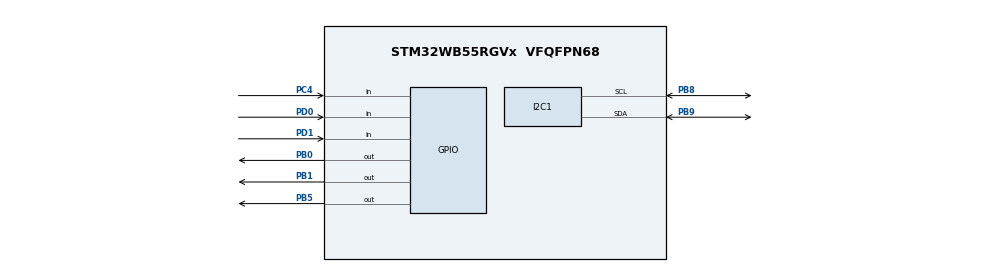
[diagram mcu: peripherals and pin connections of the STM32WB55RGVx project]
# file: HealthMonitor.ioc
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I2C1.Timing=0x00B07CB4
Mcu.Family=STM32WB
Mcu.Name=STM32WB55RGVx
Mcu.Package=VFQFPN68
NUCLEO-WB55RG.BUTTON=1
NUCLEO-WB55RG.BUTTON2=1
NUCLEO-WB55RG.BUTTON3=1
NUCLEO-WB55RG.LD1=true
NUCLEO-WB55RG.LD2=true
NUCLEO-WB55RG.LD3=true
NUCLEO-WB55RG.VCP=true
NVIC.PriorityGroup=NVIC_PRIORITYGROUP_4
OSC_IN.GPIO_Label=RCC_OSC_IN
OSC_IN.Signal=RCC_OSC_IN
OSC_OUT.GPIO_Label=RCC_OSC_OUT
OSC_OUT.Signal=RCC_OSC_OUT
PA11.GPIO_Label=USB_DM
PA11.Signal=USB_DM
PA12.GPIO_Label=USB_DP
PA12.Signal=USB_DP
PA13.GPIO_Label=JTMS
PA13.Signal=SYS_JTMS-SWDIO
PA14.GPIO_Label=JTCK
PA14.Signal=SYS_JTCK-SWCLK
PB0.Signal=GPIO_Output
PB1.Signal=GPIO_Output
PB3.GPIO_Label=JTDO
PB3.Signal=SYS_JTDO-SWO
PB5.Signal=GPIO_Output
PB6.Signal=USART1_TX
PB7.Signal=USART1_RX
PB8.Mode=I2C
PB8.Signal=I2C1_SCL
PB9.Mode=I2C
PB9.Signal=I2C1_SDA
PC13.GPIO_Label=SYS_WKUP2
PC13.Signal=SYS_WKUP2
PC14-OSC32_IN.GPIO_Label=RCC_OSC32_IN
PC14-OSC32_IN.Signal=RCC_OSC32_IN
PC15-OSC32_OUT.GPIO_Label=RCC_OSC32_OUT
PC15-OSC32_OUT.Signal=RCC_OSC32_OUT
PC4.Signal=GPIO_Input
PD0.Signal=GPIO_Input
PD1.Signal=GPIO_Input
ProjectManager.HeapSize=0x200
ProjectManager.StackSize=0x400
ProjectManager.TargetToolchain=STM32CubeIDE
RCC.ADCFreq_Value=128000000
RCC.AHBFreq_Value=32000000
RCC.APB1Freq_Value=32000000
RCC.APB1TimFreq_Value=32000000
RCC.APB2Freq_Value=32000000
RCC.APB2TimFreq_Value=32000000
RCC.APB3Freq_Value=16000000
RCC.CortexFreq_Value=32000000
RCC.HCLKFreq_Value=32000000
RCC.HSE_VALUE=32000000
RCC.HSI48_VALUE=48000000
RCC.HSI_VALUE=16000000
RCC.LSE_VALUE=32768
RCC.MSIClockRange=RCC_MSIRANGE_10
RCC.SMPSCLockSelection=RCC_SMPSCLKSOURCE_HSI
RCC.SMPSCLockSelectionVirtual=RCC_SMPSCLKSOURCE_HSI
RCC.SMPSCLockSelectionVirtualVirtual=RCC_SMPSCLKSOURCE_HSI
RCC.SMPSDivider=1
RCC.SYSCLKFreq_VALUE=32000000
RCC.USBFreq_Value=128000000
RCC.VCOOutputFreq_Value=256000000
VP_MEMORYMAP_VS_MEMORYMAP.Mode=CurAppReg
VP_NUCLEO-WB55RG_VS_BSP_COMMON.Mode=COMMON
board=NUCLEO-WB55RG

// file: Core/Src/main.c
/* USER CODE BEGIN Header */
/**
  ******************************************************************************
  * @file           : main.c
  * @brief          : Main program body
  ******************************************************************************
  * @attention
  *
  * Copyright (c) 2025 STMicroelectronics.
  * All rights reserved.
  *
  * This software is licensed under terms that can be found in the LICENSE file
  * in the root directory of this software component.
  * If no LICENSE file comes with this software, it is provided AS-IS.
  *
  ******************************************************************************
  */
/* USER CODE END Header */
#include "main.h"
#include "max30102.h"

COM_InitTypeDef BspCOMInit;
I2C_HandleTypeDef hi2c1;

void SystemClock_Config(void);
void PeriphCommonClock_Config(void);
static void MX_GPIO_Init(void);
static void MX_I2C1_Init(void);

int main(void)
{

  /* MCU Configuration--------------------------------------------------------*/

  /* Reset of all peripherals, Initializes the Flash interface and the Systick. */
  HAL_Init();

  /* Configure the system clock */
  SystemClock_Config();

  /* Configure the peripherals common clocks */
  PeriphCommonClock_Config();

  /* USER CODE BEGIN SysInit */
//  hi2c1.Instance = I2C1;
//	hi2c1.Init.Timing = 0x00B07CB4;
//	hi2c1.Init.OwnAddress1 = 0;
//	hi2c1.Init.AddressingMode = I2C_ADDRESSINGMODE_7BIT;
//	hi2c1.Init.DualAddressMode = I2C_DUALADDRESS_DISABLE;
//	hi2c1.Init.OwnAddress2 = 0;
//	hi2c1.Init.OwnAddress2Masks = I2C_OA2_NOMASK;
//	hi2c1.Init.GeneralCallMode = I2C_GENERALCALL_DISABLE;
//	hi2c1.Init.NoStretchMode = I2C_NOSTRETCH_DISABLE;
//	if (HAL_I2C_Init(&hi2c1) != HAL_OK)
//	{
//	  Error_Handler();
//	}

  /* USER CODE END SysInit */

  /* Initialize all configured peripherals */
  MX_GPIO_Init();
  MX_I2C1_Init();

  /* Initialize leds */
  BSP_LED_Init(LED_BLUE);
  BSP_LED_Init(LED_GREEN);
  BSP_LED_Init(LED_RED);

  /* Initialize USER push-button, will be used to trigger an interrupt each time it's pressed.*/
  BSP_PB_Init(BUTTON_SW1, BUTTON_MODE_EXTI);
  BSP_PB_Init(BUTTON_SW2, BUTTON_MODE_EXTI);
  BSP_PB_Init(BUTTON_SW3, BUTTON_MODE_EXTI);

  /* Initialize COM1 port (115200, 8 bits (7-bit data + 1 stop bit), no parity */
  BspCOMInit.BaudRate   = 115200;
  BspCOMInit.WordLength = COM_WORDLENGTH_8B;
  BspCOMInit.StopBits   = COM_STOPBITS_1;
  BspCOMInit.Parity     = COM_PARITY_NONE;
  BspCOMInit.HwFlowCtl  = COM_HWCONTROL_NONE;
  if (BSP_COM_Init(COM1, &BspCOMInit) != BSP_ERROR_NONE)
  {
    Error_Handler();
  }

  /* Infinite loop */
  while (1)
  {

  }
}

void SystemClock_Config(void)
{
  RCC_OscInitTypeDef RCC_OscInitStruct = {0};
  RCC_ClkInitTypeDef RCC_ClkInitStruct = {0};

  /** Configure the main internal regulator output voltage
  */
  __HAL_PWR_VOLTAGESCALING_CONFIG(PWR_REGULATOR_VOLTAGE_SCALE1);

  /** Initializes the RCC Oscillators according to the specified parameters
  * in the RCC_OscInitTypeDef structure.
  */
  RCC_OscInitStruct.OscillatorType = RCC_OSCILLATORTYPE_HSI|RCC_OSCILLATORTYPE_MSI;
  RCC_OscInitStruct.HSIState = RCC_HSI_ON;
  RCC_OscInitStruct.MSIState = RCC_MSI_ON;
  RCC_OscInitStruct.HSICalibrationValue = RCC_HSICALIBRATION_DEFAULT;
  RCC_OscInitStruct.MSICalibrationValue = RCC_MSICALIBRATION_DEFAULT;
  RCC_OscInitStruct.MSIClockRange = RCC_MSIRANGE_10;
  RCC_OscInitStruct.PLL.PLLState = RCC_PLL_NONE;
  if (HAL_RCC_OscConfig(&RCC_OscInitStruct) != HAL_OK)
  {
    Error_Handler();
  }

  /** Configure the SYSCLKSource, HCLK, PCLK1 and PCLK2 clocks dividers
  */
  RCC_ClkInitStruct.ClockType = RCC_CLOCKTYPE_HCLK4|RCC_CLOCKTYPE_HCLK2
                              |RCC_CLOCKTYPE_HCLK|RCC_CLOCKTYPE_SYSCLK
                              |RCC_CLOCKTYPE_PCLK1|RCC_CLOCKTYPE_PCLK2;
  RCC_ClkInitStruct.SYSCLKSource = RCC_SYSCLKSOURCE_MSI;
  RCC_ClkInitStruct.AHBCLKDivider = RCC_SYSCLK_DIV1;
  RCC_ClkInitStruct.APB1CLKDivider = RCC_HCLK_DIV1;
  RCC_ClkInitStruct.APB2CLKDivider = RCC_HCLK_DIV1;
  RCC_ClkInitStruct.AHBCLK2Divider = RCC_SYSCLK_DIV1;
  RCC_ClkInitStruct.AHBCLK4Divider = RCC_SYSCLK_DIV1;

  if (HAL_RCC_ClockConfig(&RCC_ClkInitStruct, FLASH_LATENCY_1) != HAL_OK)
  {
    Error_Handler();
  }
}

void PeriphCommonClock_Config(void)
{
  RCC_PeriphCLKInitTypeDef PeriphClkInitStruct = {0};

  /** Initializes the peripherals clock
  */
  PeriphClkInitStruct.PeriphClockSelection = RCC_PERIPHCLK_SMPS;
  PeriphClkInitStruct.SmpsClockSelection = RCC_SMPSCLKSOURCE_HSI;
  PeriphClkInitStruct.SmpsDivSelection = RCC_SMPSCLKDIV_RANGE0;

  if (HAL_RCCEx_PeriphCLKConfig(&PeriphClkInitStruct) != HAL_OK)
  {
    Error_Handler();
  }
}

static void MX_I2C1_Init(void)
{

  hi2c1.Instance = I2C1;
  hi2c1.Init.Timing = 0x00B07CB4;
  hi2c1.Init.OwnAddress1 = 0;
  hi2c1.Init.AddressingMode = I2C_ADDRESSINGMODE_7BIT;
  hi2c1.Init.DualAddressMode = I2C_DUALADDRESS_DISABLE;
  hi2c1.Init.OwnAddress2 = 0;
  hi2c1.Init.OwnAddress2Masks = I2C_OA2_NOMASK;
  hi2c1.Init.GeneralCallMode = I2C_GENERALCALL_DISABLE;
  hi2c1.Init.NoStretchMode = I2C_NOSTRETCH_DISABLE;
  if (HAL_I2C_Init(&hi2c1) != HAL_OK)
  {
    Error_Handler();
  }

  /** Configure Analogue filter
  */
  if (HAL_I2CEx_ConfigAnalogFilter(&hi2c1, I2C_ANALOGFILTER_ENABLE) != HAL_OK)
  {
    Error_Handler();
  }

  /** Configure Digital filter
  */
  if (HAL_I2CEx_ConfigDigitalFilter(&hi2c1, 0) != HAL_OK)
  {
    Error_Handler();
  }

}

static void MX_GPIO_Init(void)
{
  GPIO_InitTypeDef GPIO_InitStruct = {0};

  /* GPIO Ports Clock Enable */
  __HAL_RCC_GPIOC_CLK_ENABLE();
  __HAL_RCC_GPIOB_CLK_ENABLE();
  __HAL_RCC_GPIOA_CLK_ENABLE();

  /*Configure GPIO pins : USB_DM_Pin USB_DP_Pin */
  GPIO_InitStruct.Pin = USB_DM_Pin|USB_DP_Pin;
  GPIO_InitStruct.Mode = GPIO_MODE_AF_PP;
  GPIO_InitStruct.Pull = GPIO_NOPULL;
  GPIO_InitStruct.Speed = GPIO_SPEED_FREQ_LOW;
  GPIO_InitStruct.Alternate = GPIO_AF10_USB;
  HAL_GPIO_Init(GPIOA, &GPIO_InitStruct);

}

void Error_Handler(void)
{
  __disable_irq();
  while (1)
  {
  }
}
